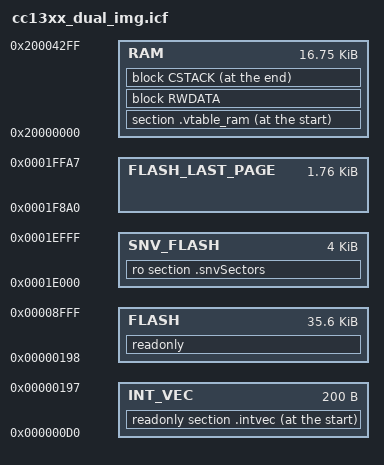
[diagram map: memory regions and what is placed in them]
/******************************************************************************

 @file  cc13xx_dual_img.icf

 @brief IAR ARM Linker Configuration File - BLE Stack

        Note: Code stack and heap are allocated by the Application/RTOS build.

        Imported Symbols
        Note: Linker defines are located in the IAR IDE project using
        --config_def in Options->Linker->Extra Options, or placed in
        Options->Linker-> Config->Configuration file symbol definitions.

        CCxxxx:             Device Name (e.g. CC2650). In order to define this
                            symbol, the tool chain requires that it be set to
                            a specific value, but in fact, the actual value does
                            not matter as it is not used in the linker control
                            file. The only way this symbol is used is based on
                            whether it is defined or not, not its actual value.
                            There are other linker symbols that do specifically
                            set their value to 1 to indicate R1, and 2 to
                            indicate R2, and these values are checked and do make
                            a difference. However, it would appear confusing if
                            the device name's value did not correspond to the
                            value set in other linker symbols. In order to avoid
                            this confusion, when the symbol is defined, it should
                            be set to the value of the device's ROM that it
                            corresponds so as to look and feel consistent. Please
                            note that a device name symbol should always be
                            defined to avoid side effects from default values
                            that may not be correct for the device being used.
        FLASH_ONLY_BUILD:   Build full BLE stack in flash only memory.
        FLASH_ROM_BUILD:    Build Flash portion of BLE stack to work with
                            ROM code.
        ROM_BUILD:          Build ROM portion of BLE stack.
        COMMON_ROM_BUILD:   Build of common ROM code.
        TEST_ROM_IN_FLASH:  Build ROM code in Flash memory to test.
        ICALL_STACK0_START: Start address of flash only and flash ROM
                            builds.

        Exported Symbols
        Note: Can be used as externs in C code.

        ROM_BASE_ADDR:        Location of start of ROM (where RT Init is
                              expected).
        RAM_BASE_ADDR:        Location of start of RAM (for ICall and JT
                              pointers).
        COMMON_RAM_BASE_ADDR: Location of start of RAM (for ICall and JT
                              pointers).
        PAGE_SIZE:            Size of Flash sector, in bytes.
        NUM_SNV_PAGES:        Number of sectors used for Simple NV.

 Group: WCS, BTS
 Target Device: cc13xx_cc26xx

 ******************************************************************************
 
 Copyright (c) 2013-2022, Texas Instruments Incorporated
 All rights reserved.

 Redistribution and use in source and binary forms, with or without
 modification, are permitted provided that the following conditions
 are met:

 *  Redistributions of source code must retain the above copyright
    notice, this list of conditions and the following disclaimer.

 *  Redistributions in binary form must reproduce the above copyright
    notice, this list of conditions and the following disclaimer in the
    documentation and/or other materials provided with the distribution.

 *  Neither the name of Texas Instruments Incorporated nor the names of
    its contributors may be used to endorse or promote products derived
    from this software without specific prior written permission.

 THIS SOFTWARE IS PROVIDED BY THE COPYRIGHT HOLDERS AND CONTRIBUTORS "AS IS"
 AND ANY EXPRESS OR IMPLIED WARRANTIES, INCLUDING, BUT NOT LIMITED TO,
 THE IMPLIED WARRANTIES OF MERCHANTABILITY AND FITNESS FOR A PARTICULAR
 PURPOSE ARE DISCLAIMED. IN NO EVENT SHALL THE COPYRIGHT OWNER OR
 CONTRIBUTORS BE LIABLE FOR ANY DIRECT, INDIRECT, INCIDENTAL, SPECIAL,
 EXEMPLARY, OR CONSEQUENTIAL DAMAGES (INCLUDING, BUT NOT LIMITED TO,
 PROCUREMENT OF SUBSTITUTE GOODS OR SERVICES; LOSS OF USE, DATA, OR PROFITS;
 OR BUSINESS INTERRUPTION) HOWEVER CAUSED AND ON ANY THEORY OF LIABILITY,
 WHETHER IN CONTRACT, STRICT LIABILITY, OR TORT (INCLUDING NEGLIGENCE OR
 OTHERWISE) ARISING IN ANY WAY OUT OF THE USE OF THIS SOFTWARE,
 EVEN IF ADVISED OF THE POSSIBILITY OF SUCH DAMAGE.

 ******************************************************************************
 
 
 *****************************************************************************/

////////////////////////////////////////////////////////////////////////////////
// Memory Sizes
////////////////////////////////////////////////////////////////////////////////

  define symbol RAM_SIZE            = 0x00005000;  // 20K
  define symbol FLASH_SIZE          = 0x00020000;  // 128K
  define symbol ROM_SIZE            = 0x0001C000;  // 115K

////////////////////////////////////////////////////////////////////////////////

////////////////////////////////////////////////////////////////////////////////
// Memory Definitions
////////////////////////////////////////////////////////////////////////////////

////////////////////////////////////////////////////////////////////////////////
// RAM
//

define symbol RAM_START             = 0x20000000;

  if ( isdefinedsymbol(ICALL_RAM0_START) )
  {
    define symbol RAM_END           = (ICALL_RAM0_START-1);
  }
  else // default
  {
    define symbol RAM_END           = 0x200042FF;
  }

////////////////////////////////////////////////////////////////////////////////
// Flash
//

// Custon Image start location
if ( isdefinedsymbol(APP_IMAGE_START) )
{
  define symbol FLASH_START         = APP_IMAGE_START;

  // Custom Image sizes.
  if ( isdefinedsymbol(APP_IMAGE_SIZE) )
  {
    define symbol IMAGE_SIZE        = APP_IMAGE_SIZE;
  }
  else
  {
    if ( isdefinedsymbol(RTOS_ROM) )
    {
      // Default for RTOS in ROM build.  This assumes that the application is
      // also using some space on page 31 (0x1F).
      define symbol IMAGE_SIZE      = 0x5000;
    }
    else
    {
      // Default RTOS in Flash build.  This is the maximum size for the larger
      // image, assuming Stack image starts at address 0xF000.
      define symbol IMAGE_SIZE      = 0x9000;
    }
  }

  define symbol FLASH_END           = APP_IMAGE_START + IMAGE_SIZE - 1;
}
else // Default
{
  if ( isdefinedsymbol(RTOS_ROM) )
  {
    // Default for Image A region, RTOS in ROM size.
    define symbol FLASH_START         = 0x00D0;
    define symbol FLASH_END           = 0x8FFF;

    // For cc13xx, the start of the image is claimed by the RTOS vectors.
    // This is the first available slot.
    define symbol INT_VEC_START       = FLASH_START;
  }
  else
  {
    // Default for Image B region, RTOS in Flash size.
    define symbol FLASH_START         = 0x00009000;
    define symbol FLASH_END           = ICALL_STACK0_START - 1;
    define symbol INT_VEC_START   = FLASH_START;
  }
}
define symbol INT_VEC_SIZE    = 0xC8;

define symbol INT_VEC_END     = INT_VEC_START + INT_VEC_SIZE - 1;

define symbol IMG_FLASH_START = INT_VEC_START + INT_VEC_SIZE;

// Symbols only used by Image B to reference SNV Flash Page.
define symbol SNV_FLASH_START = 0x0001E000;
define symbol SNV_FLASH_END   = 0x0001EFFF;

////////////////////////////////////////////////////////////////////////////////
// Stack
//

define symbol STACK_SIZE           = 0x400;
define symbol STACK_START          = RAM_END + 1;
define symbol STACK_END            = STACK_START - STACK_SIZE;
//
define symbol STACK_TOP            = RAM_END + 1;
export symbol STACK_TOP;

////////////////////////////////////////////////////////////////////////////////
// Flash Interrupt Vector Table
//

define symbol INTVEC_NUM_ENTRIES   = 50 + 1; // first entry is stack location
define symbol INTVEC_SIZE          = INTVEC_NUM_ENTRIES + 4;

////////////////////////////////////////////////////////////////////////////////
// Memory Regions
////////////////////////////////////////////////////////////////////////////////

define memory mem with size = 4G;

define region INT_VEC         = mem:[from INT_VEC_START   to INT_VEC_END];

if ( isdefinedsymbol(RTOS_ROM) )
{
  define region FLASH_LAST_PAGE = mem:[from 0x1F8A0 to 0x1FFA7];
  define region FLASH           = mem:[from IMG_FLASH_START to FLASH_END]
                                  | FLASH_LAST_PAGE;
}
else
{
  define region FLASH           = mem:[from IMG_FLASH_START to FLASH_END];

  define region SNV_FLASH       = mem:[from SNV_FLASH_START to SNV_FLASH_END];
}


define region RAM             = mem:[from RAM_START       to RAM_END];

////////////////////////////////////////////////////////////////////////////////
// Memory Placement
// For ROM: C Runtime, Checksum, ROM Revision Number, Flash JT, and FPB.
////////////////////////////////////////////////////////////////////////////////

// Interrupt Vector Table
place at start of INT_VEC       { readonly section .intvec };
keep                            { readonly section .intvec };

// Code and RO Data
place in FLASH                  { readonly };

if ( !isdefinedsymbol(RTOS_ROM) )
{
  place in SNV_FLASH            { ro section .snvSectors };
}

// RAM Vector Table
place at start of RAM           { section .vtable_ram };

// RW Data
define block RWDATA { rw };
place in RAM { block RWDATA };

// Runtime Stack
define block CSTACK with alignment = 8, size = STACK_SIZE { section .stack };
place at end of RAM             { block CSTACK };

////////////////////////////////////////////////////////////////////////////////
// Initialization
////////////////////////////////////////////////////////////////////////////////

initialize by copy { readwrite };

do not initialize
{
  section .noinit,
  section .stack,
};

////////////////////////////////////////////////////////////////////////////////
// The USE_TIRTOS_ROM symbol is defined internally in the build flow (using
// --config_def USE_TIRTOS_ROM=1) for TI-RTOS applications whose appBLE.cfg file
// specifies to use the ROM.
//
if (isdefinedsymbol(USE_TIRTOS_ROM)) {
     include "TIRTOS_ROM.icf";
}
